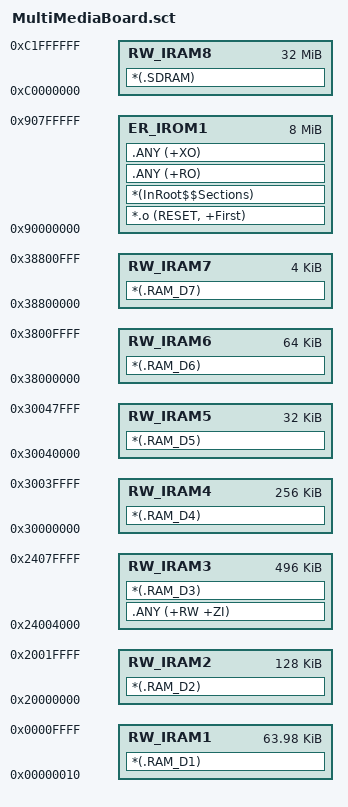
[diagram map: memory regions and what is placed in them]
; *************************************************************
; *** Scatter-Loading Description File generated by uVision ***
; *************************************************************

LR_IROM1 0x90000000 0x00800000  {    	; load region size_region
	ER_IROM1 0x90000000 0x00800000  {  	; load address = execution address
		*.o (RESET, +First)
		*(InRoot$$Sections)
		.ANY (+RO)
		.ANY (+XO)
	}

	; RW data - 64KB ITCM - Only for CPU and MDMA, Start From 0x10 in oder to avoid NULL
	RW_IRAM1 0x00000010 0x0000FFF0{
		*(.RAM_D1)
	}

	; RW data - 128KB DTCM - Only for CPU and MDMA
	RW_IRAM2 0x20000000 0x00020000 {
		*(.RAM_D2)
	}
	
	; RW data - 512KB AXI SRAM - 16KB
	RW_IRAM3 0x24004000 0x0007C000 {
		.ANY (+RW +ZI)
		*(.RAM_D3)
	}
	
	; RW data - 128KB SRAM1(0x30000000) + 128KB SRAM2(0x30020000)
	RW_IRAM4 0x30000000 0x00040000 {
		*(.RAM_D4)
	}
	
	; RW data - 32KB SRAM3(0x30040000)
	; SRAM3 is commonly used for ETH
	RW_IRAM5 0x30040000	0x00008000 {
		*(.RAM_D5)
	}
	
	; RW data - 64KB SRAM4(0x38000000)
	RW_IRAM6 0x38000000 0x00010000 {
		*(.RAM_D6)
	}
	
	; RW data - 4KB Backup SRAM4(0x38800000)
	RW_IRAM7 0x38800000 0x00001000 {
		*(.RAM_D7)
	}
	
	RW_IRAM8 0xC0000000  0x02000000  {  ; RW data - 32MB SDRAM(0xC0000000)
		*(.SDRAM)
	}
}

